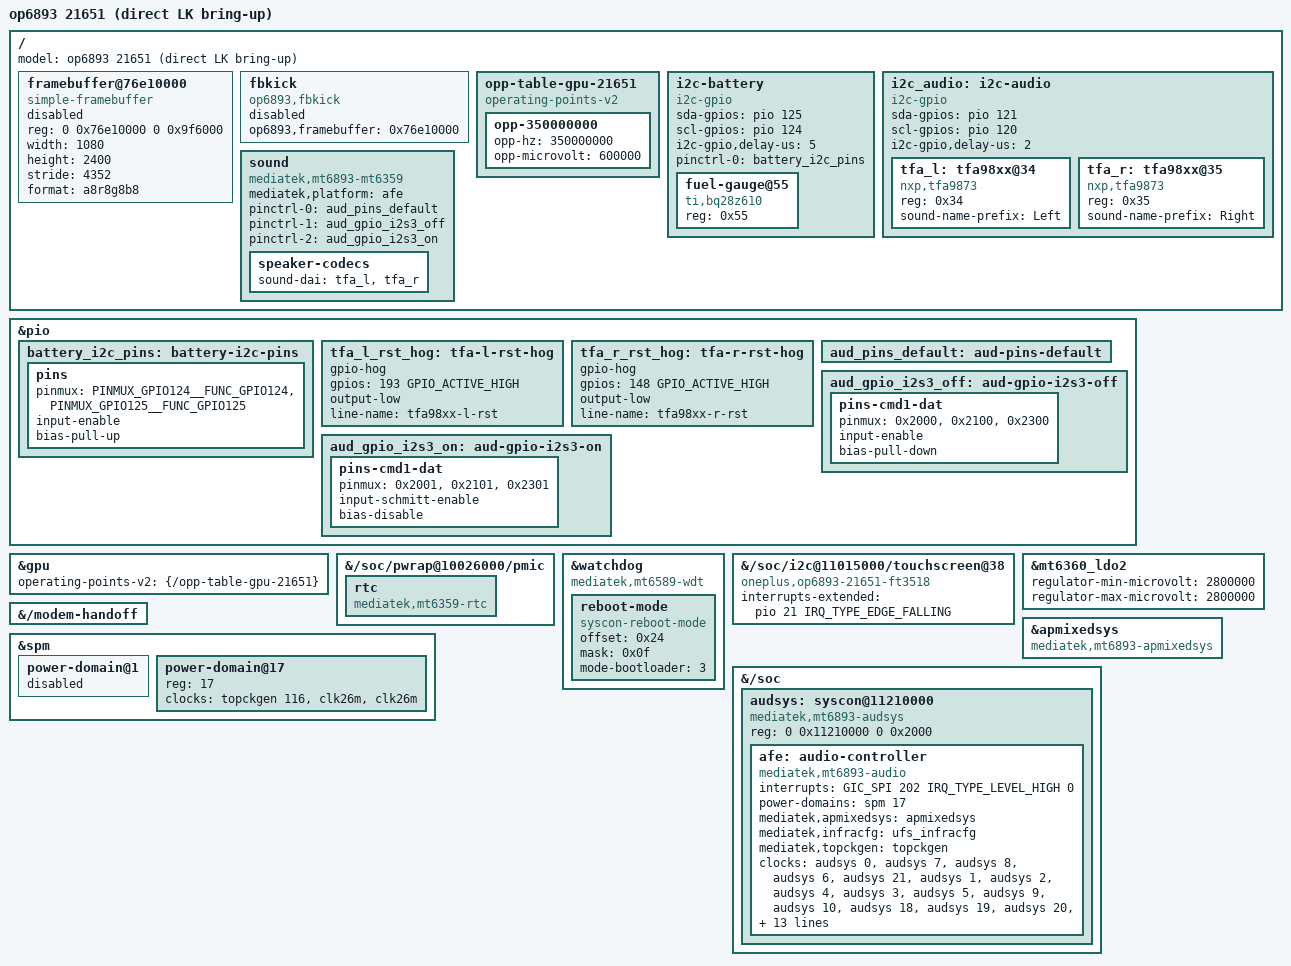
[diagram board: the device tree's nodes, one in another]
// SPDX-License-Identifier: GPL-2.0-only
#include "mt6893-op6893-boot.dts"

/ {
	model = "op6893 21651 (direct LK bring-up)";

	/delete-node/ framebuffer@796fc000;
	/delete-node/ fbkick;
	/delete-node/ gpu-probe;

	framebuffer@76e10000 {
		compatible = "simple-framebuffer";
		reg = <0 0x76e10000 0 0x9f6000>;
		width = <1080>;
		height = <2400>;
		stride = <4352>;
		format = "a8r8g8b8";
		status = "disabled"; /* enabled only after LK reservation check */
	};

	fbkick {
		compatible = "op6893,fbkick";
		op6893,framebuffer = <0x76e10000>;
		status = "disabled";
	};

	opp-table-gpu-21651 {
		compatible = "operating-points-v2";

		opp-350000000 {
			opp-hz = /bits/ 64 <350000000>;
			opp-microvolt = <600000>;
		};
	};

	i2c-battery {
		compatible = "i2c-gpio";
		sda-gpios = <&pio 125 (GPIO_ACTIVE_HIGH | GPIO_OPEN_DRAIN)>;
		scl-gpios = <&pio 124 (GPIO_ACTIVE_HIGH | GPIO_OPEN_DRAIN)>;
		i2c-gpio,delay-us = <5>;
		pinctrl-names = "default";
		pinctrl-0 = <&battery_i2c_pins>;
		#address-cells = <1>;
		#size-cells = <0>;

		fuel-gauge@55 {
			compatible = "ti,bq28z610";
			reg = <0x55>;
		};
	};
};

&pio {
	battery_i2c_pins: battery-i2c-pins {
		pins {
			pinmux = <PINMUX_GPIO124__FUNC_GPIO124>,
				 <PINMUX_GPIO125__FUNC_GPIO125>;
			input-enable;
			bias-pull-up;
		};
	};
};

&gpu {
	operating-points-v2 = <&{/opp-table-gpu-21651}>;
};

&{/soc/pwrap@10026000/pmic} {
	rtc {
		compatible = "mediatek,mt6359-rtc", "mediatek,mt6358-rtc";
	};
};

&watchdog {
	compatible = "mediatek,mt6589-wdt", "syscon", "simple-mfd";

	reboot-mode {
		compatible = "syscon-reboot-mode";
		offset = <0x24>;
		mask = <0x0f>;
		mode-bootloader = <3>;
	};
};

&{/soc/i2c@11015000/touchscreen@38} {
	compatible = "oneplus,op6893-21651-ft3518", "focaltech,ft3518";
	interrupts-extended = <&pio 21 IRQ_TYPE_EDGE_FALLING>;
};

&mt6360_ldo2 {
	regulator-min-microvolt = <2800000>;
	regulator-max-microvolt = <2800000>;
};

/*
 * Read-only LK handoff inspection. 21651 is flashed with 20615's LK and DTBO,
 * so the mblock regions inherited from the shared board file are only an
 * assumption until the tag header and the SMEM subregions are validated on
 * this unit. The cold modem platform node stays disabled.
 */
&{/modem-handoff} {
	status = "okay";
};

&apmixedsys {
	compatible = "mediatek,mt6893-apmixedsys", "syscon";
};

&spm {
	power-domain@1 {
		status = "disabled";
	};

	power-domain@17 {
		reg = <17>;
		clocks = <&topckgen 116>, <&clk26m>, <&clk26m>;
		clock-names = "audio", "audio1", "audio2";
		#power-domain-cells = <0>;
	};
};

&{/soc} {
	audsys: syscon@11210000 {
		compatible = "mediatek,mt6893-audsys", "syscon", "simple-mfd";
		reg = <0 0x11210000 0 0x2000>;
		#clock-cells = <1>;

		afe: audio-controller {
			compatible = "mediatek,mt6893-audio";
			interrupts = <GIC_SPI 202 IRQ_TYPE_LEVEL_HIGH 0>;
			power-domains = <&spm 17>;
			mediatek,apmixedsys = <&apmixedsys>;
			mediatek,infracfg = <&ufs_infracfg>;
			mediatek,topckgen = <&topckgen>;
			clocks = <&audsys 0>, <&audsys 7>, <&audsys 8>,
				 <&audsys 6>, <&audsys 21>, <&audsys 1>,
				 <&audsys 2>, <&audsys 4>, <&audsys 3>,
				 <&audsys 5>, <&audsys 9>, <&audsys 10>,
				 <&audsys 18>, <&audsys 19>, <&audsys 20>,
				 <&audsys 22>, <&audsys 23>, <&audsys 24>,
				 <&audsys 25>, <&audsys 26>, <&clk26m>,
				 <&clk26m>, <&topckgen 115>, <&topckgen 116>,
				 <&topckgen 4>, <&topckgen 135>, <&apmixedsys 13>,
				 <&topckgen 136>, <&apmixedsys 14>, <&topckgen 131>,
				 <&topckgen 49>, <&topckgen 132>, <&topckgen 52>,
				 <&topckgen 150>, <&topckgen 151>, <&topckgen 152>,
				 <&topckgen 153>, <&topckgen 154>, <&topckgen 155>,
				 <&topckgen 156>, <&topckgen 157>, <&topckgen 158>,
				 <&topckgen 159>, <&topckgen 162>, <&topckgen 163>,
				 <&topckgen 164>, <&topckgen 165>, <&topckgen 166>,
				 <&topckgen 167>, <&topckgen 168>, <&topckgen 170>,
				 <&topckgen 171>, <&topckgen 172>, <&topckgen 173>,
				 <&topckgen 144>, <&clk26m>;
			clock-names = "aud_afe_clk", "aud_dac_clk", "aud_dac_predis_clk",
				      "aud_adc_clk", "aud_adda6_adc_clk", "aud_apll22m_clk",
				      "aud_apll24m_clk", "aud_apll1_tuner_clk", "aud_apll2_tuner_clk",
				      "aud_tdm_clk", "aud_tml_clk", "aud_nle",
				      "aud_dac_hires_clk", "aud_adc_hires_clk", "aud_adc_hires_tml",
				      "aud_adda6_adc_hires_clk", "aud_3rd_dac_clk", "aud_3rd_dac_predis_clk",
				      "aud_3rd_dac_tml", "aud_3rd_dac_hires_clk", "aud_infra_clk",
				      "aud_infra_26m_clk", "top_mux_audio", "top_mux_audio_int",
				      "top_mainpll_d4_d4", "top_mux_aud_1", "top_apll1_ck",
				      "top_mux_aud_2", "top_apll2_ck", "top_mux_aud_eng1",
				      "top_apll1_d4", "top_mux_aud_eng2", "top_apll2_d4",
				      "top_i2s0_m_sel", "top_i2s1_m_sel", "top_i2s2_m_sel",
				      "top_i2s3_m_sel", "top_i2s4_m_sel", "top_i2s5_m_sel",
				      "top_i2s6_m_sel", "top_i2s7_m_sel", "top_i2s8_m_sel",
				      "top_i2s9_m_sel", "top_apll12_div0", "top_apll12_div1",
				      "top_apll12_div2", "top_apll12_div3", "top_apll12_div4",
				      "top_apll12_divb", "top_apll12_div5", "top_apll12_div6",
				      "top_apll12_div7", "top_apll12_div8", "top_apll12_div9",
				      "top_mux_audio_h", "top_clk26m_clk";
		};
	};
};

&pio {
	tfa_l_rst_hog: tfa-l-rst-hog {
		gpio-hog;
		gpios = <193 GPIO_ACTIVE_HIGH>;
		output-low;
		line-name = "tfa98xx-l-rst";
	};

	tfa_r_rst_hog: tfa-r-rst-hog {
		gpio-hog;
		gpios = <148 GPIO_ACTIVE_HIGH>;
		output-low;
		line-name = "tfa98xx-r-rst";
	};

	aud_pins_default: aud-pins-default {
	};

	aud_gpio_i2s3_off: aud-gpio-i2s3-off {
		pins-cmd1-dat {
			pinmux = <0x2000>, <0x2100>, <0x2300>;
			input-enable;
			bias-pull-down;
		};
	};

	aud_gpio_i2s3_on: aud-gpio-i2s3-on {
		pins-cmd1-dat {
			pinmux = <0x2001>, <0x2101>, <0x2301>;
			input-schmitt-enable;
			bias-disable;
		};
	};
};

/ {
	i2c_audio: i2c-audio {
		compatible = "i2c-gpio";
		sda-gpios = <&pio 121 (GPIO_ACTIVE_HIGH | GPIO_OPEN_DRAIN)>;
		scl-gpios = <&pio 120 (GPIO_ACTIVE_HIGH | GPIO_OPEN_DRAIN)>;
		i2c-gpio,delay-us = <2>;
		#address-cells = <1>;
		#size-cells = <0>;

		tfa_l: tfa98xx@34 {
			compatible = "nxp,tfa9873";
			reg = <0x34>;
			#sound-dai-cells = <0>;
			sound-name-prefix = "Left";
		};

		tfa_r: tfa98xx@35 {
			compatible = "nxp,tfa9873";
			reg = <0x35>;
			#sound-dai-cells = <0>;
			sound-name-prefix = "Right";
		};
	};

	sound: sound {
		compatible = "mediatek,mt6893-mt6359";
		mediatek,platform = <&afe>;
		pinctrl-names = "default", "aud_gpio_i2s3_off", "aud_gpio_i2s3_on";
		pinctrl-0 = <&aud_pins_default>;
		pinctrl-1 = <&aud_gpio_i2s3_off>;
		pinctrl-2 = <&aud_gpio_i2s3_on>;

		speaker-codecs {
			sound-dai = <&tfa_l>, <&tfa_r>;
		};
	};
};
